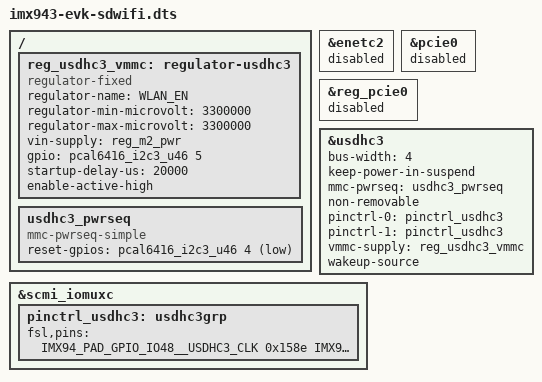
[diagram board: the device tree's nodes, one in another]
// SPDX-License-Identifier: (GPL-2.0+ OR MIT)
/*
 * Copyright 2025 NXP
 */

#include "imx943-evk.dts"

/ {
	reg_usdhc3_vmmc: regulator-usdhc3 {
		compatible = "regulator-fixed";
		regulator-name = "WLAN_EN";
		regulator-min-microvolt = <3300000>;
		regulator-max-microvolt = <3300000>;
		vin-supply = <&reg_m2_pwr>;
		gpio = <&pcal6416_i2c3_u46 5 GPIO_ACTIVE_HIGH>;
		/*
		 * IW612 wifi chip needs more delay than other wifi chips to complete
		 * the host interface initialization after power up, otherwise the
		 * internal state of IW612 may be unstable, resulting in the failure of
		 * the SDIO3.0 switch voltage.
		 */
		startup-delay-us = <20000>;
		enable-active-high;
	};

	usdhc3_pwrseq: usdhc3_pwrseq {
		compatible = "mmc-pwrseq-simple";
		reset-gpios = <&pcal6416_i2c3_u46 4 GPIO_ACTIVE_LOW>;
	};
};

/*
 * Since usdhc3 has issue with single GPIO_IO48 pad for usdhc3 clk, need to
 * add ETH4_TX_CLK pad for usdhc3 clock internal reference, otherwise usdhc3
 * can't trigger transfer complete interrupt.
 * Disable enetc2 due to pin conflict.
 */
&enetc2 {
	status = "disabled";
};

&pcie0 {
	status = "disabled";
};

&reg_pcie0 {
	status = "disabled";
};

&usdhc3 {
	bus-width = <4>;
	keep-power-in-suspend;
	mmc-pwrseq = <&usdhc3_pwrseq>;
	non-removable;
	/*
	 * Only enable SDIO2.0 mode as the corresponding GPIO pads are 3.3V, the
	 * max frequency is 50MHz.
	 */
	pinctrl-0 = <&pinctrl_usdhc3>;
	pinctrl-1 = <&pinctrl_usdhc3>;
	pinctrl-names = "default", "sleep";
	vmmc-supply = <&reg_usdhc3_vmmc>;
	wakeup-source;
	status = "okay";
};

&scmi_iomuxc {
	pinctrl_usdhc3: usdhc3grp {
		fsl,pins = <
			IMX94_PAD_GPIO_IO48__USDHC3_CLK		0x158e
			IMX94_PAD_ETH4_TX_CLK__USDHC3_CLK	0x158e
			IMX94_PAD_GPIO_IO49__USDHC3_CMD		0x138e
			IMX94_PAD_GPIO_IO50__USDHC3_DATA0	0x138e
			IMX94_PAD_GPIO_IO51__USDHC3_DATA1	0x138e
			IMX94_PAD_GPIO_IO52__USDHC3_DATA2	0x138e
			IMX94_PAD_GPIO_IO53__USDHC3_DATA3	0x138e
		>;
	};
};
